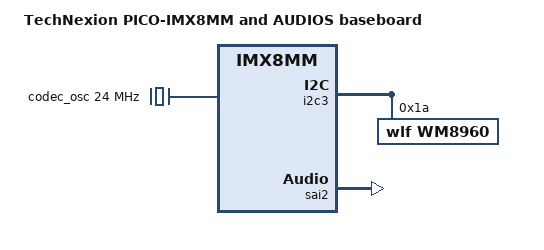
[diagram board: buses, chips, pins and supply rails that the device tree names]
/*
 * Copyright 2020 Audink Inc.
 * Copyright 2020 Audios
 *
 * Author: Erik Young <erik.young@audios.com>
 *
 * This program is free software; you can redistribute it and/or
 * modify it under the terms of the GNU General Public License
 * as published by the Free Software Foundation; either version 2
 * of the License, or (at your option) any later version.
 *
 * This program is distributed in the hope that it will be useful,
 * but WITHOUT ANY WARRANTY; without even the implied warranty of
 * MERCHANTABILITY or FITNESS FOR A PARTICULAR PURPOSE.  See the
 * GNU General Public License for more details.
 */

/dts-v1/;

#include <dt-bindings/input/input.h>
#include "imx8mm-pico.dtsi"

/ {
        model = "TechNexion PICO-IMX8MM and AUDIOS baseboard";
        compatible = "fsl,imx8mm-pico", "fsl,imx8mm";

        /* DAI Link Driver */
        sound-wm8960 {
                compatible = "fsl,imx-audio-wm8960";
                model = "wm8960-audio";
                cpu-dai = <&sai2>;
                codec-master;
                audio-codec = <&wm8960>;
                audio-routing =
                        "Headphone Jack", "HP_L",
                        "Headphone Jack", "HP_R",
                        "Ext Spk", "SPK_LP",
                        "Ext Spk", "SPK_LN",
                        "Ext Spk", "SPK_RP",
                        "Ext Spk", "SPK_RN",
                        "LINPUT1", "Main MIC",
                        "RINPUT1", "Main MIC",
                        "Main MIC", "MICB";
                /* JD2: hp detect high for headphone*/
                hp-det = <2 0>;
        };

        clocks {
                codec_osc: aud_mclk {
                        compatible = "fixed-clock";
                        #clock-cells = <0>;
                        clock-frequency = <24000000>;
                        clock-output-names = "wm8960-mclk";
                };
        };
};

&i2c3 {
        status = "okay";

        /* Codec Driver */
        wm8960: codec@1a {
                compatible = "wlf,wm8960";
                #sound-dai-cells = <0>;
                reg = <0x1a>;
                clocks = <&codec_osc>;
                clock-names = "mclk";
                wlf,shared-lrclk;
                wlf,fixed-mclk;
        };
};

&sai2 {
        status = "okay";
};

&pwm4 {
        status = "disabled";
};

&pwm1 {
        status = "disabled";
};
